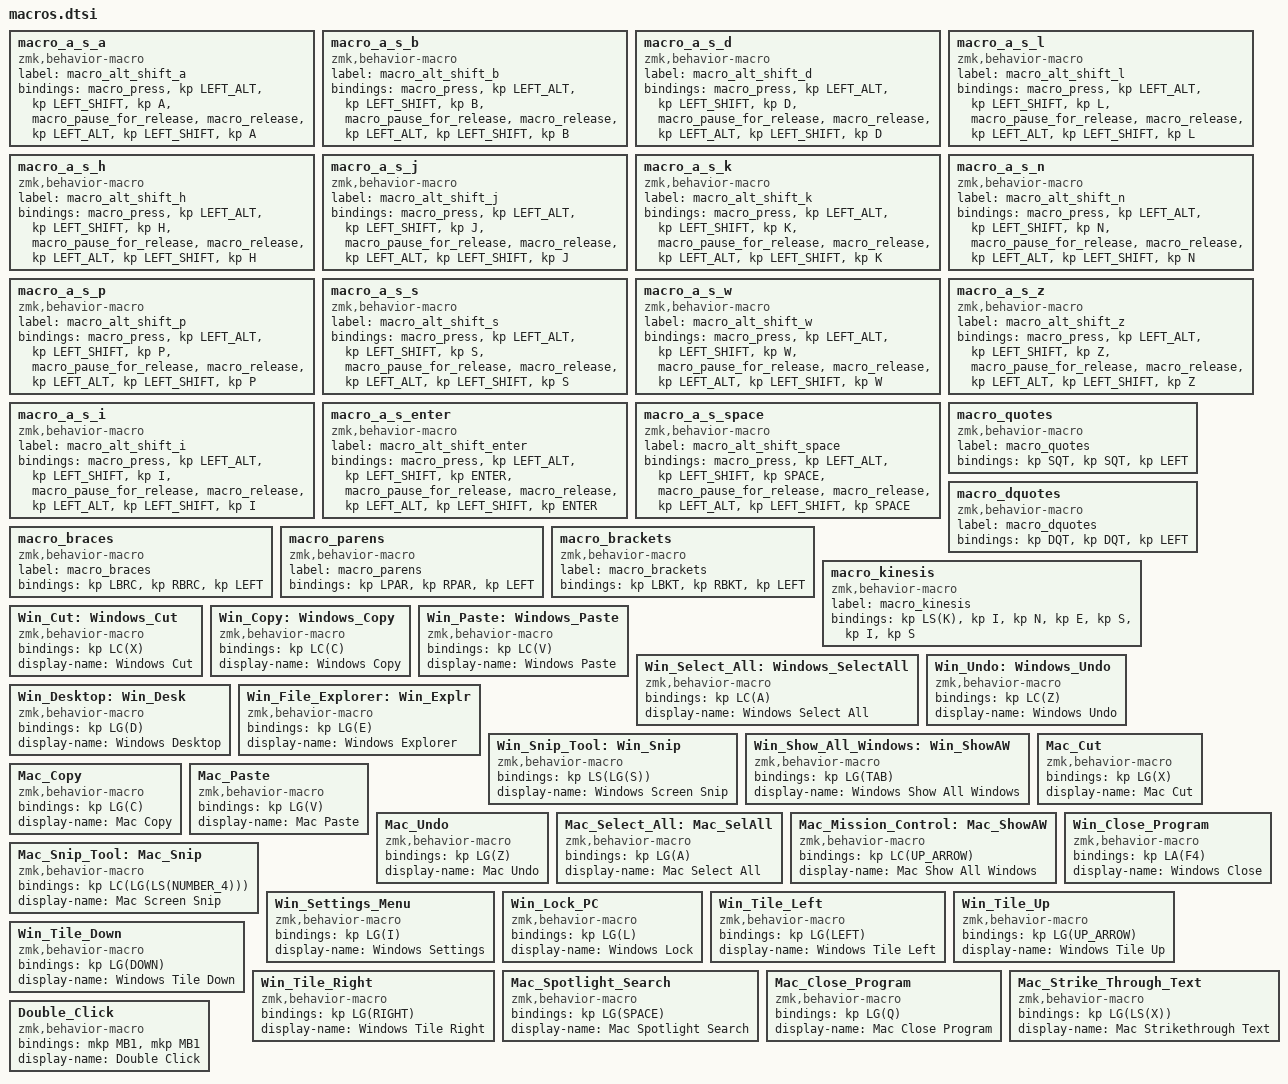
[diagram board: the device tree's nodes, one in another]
macro_a_s_a: macro_a_s_a{
compatible = "zmk,behavior-macro";
label = "macro_alt_shift_a";
#binding-cells = <0>;
bindings = <&macro_press &kp LEFT_ALT &kp LEFT_SHIFT &kp A>, <&macro_pause_for_release>, <&macro_release &kp LEFT_ALT &kp LEFT_SHIFT &kp A>;
};
macro_a_s_b: macro_a_s_b{
compatible = "zmk,behavior-macro";
label = "macro_alt_shift_b";
#binding-cells = <0>;
bindings = <&macro_press &kp LEFT_ALT &kp LEFT_SHIFT &kp B>, <&macro_pause_for_release>, <&macro_release &kp LEFT_ALT &kp LEFT_SHIFT &kp B>;
};
macro_a_s_d: macro_a_s_d{
compatible = "zmk,behavior-macro";
label = "macro_alt_shift_d";
#binding-cells = <0>;
bindings = <&macro_press &kp LEFT_ALT &kp LEFT_SHIFT &kp D>, <&macro_pause_for_release>, <&macro_release &kp LEFT_ALT &kp LEFT_SHIFT &kp D>;
};
macro_a_s_l: macro_a_s_l{
compatible = "zmk,behavior-macro";
label = "macro_alt_shift_l";
#binding-cells = <0>;
bindings = <&macro_press &kp LEFT_ALT &kp LEFT_SHIFT &kp L>, <&macro_pause_for_release>, <&macro_release &kp LEFT_ALT &kp LEFT_SHIFT &kp L>;
};
macro_a_s_h: macro_a_s_h{
compatible = "zmk,behavior-macro";
label = "macro_alt_shift_h";
#binding-cells = <0>;
bindings = <&macro_press &kp LEFT_ALT &kp LEFT_SHIFT &kp H>, <&macro_pause_for_release>, <&macro_release &kp LEFT_ALT &kp LEFT_SHIFT &kp H>;
};
macro_a_s_j: macro_a_s_j{
compatible = "zmk,behavior-macro";
label = "macro_alt_shift_j";
#binding-cells = <0>;
bindings = <&macro_press &kp LEFT_ALT &kp LEFT_SHIFT &kp J>, <&macro_pause_for_release>, <&macro_release &kp LEFT_ALT &kp LEFT_SHIFT &kp J>;
};
macro_a_s_k: macro_a_s_k{
compatible = "zmk,behavior-macro";
label = "macro_alt_shift_k";
#binding-cells = <0>;
bindings = <&macro_press &kp LEFT_ALT &kp LEFT_SHIFT &kp K>, <&macro_pause_for_release>, <&macro_release &kp LEFT_ALT &kp LEFT_SHIFT &kp K>;
};
macro_a_s_n: macro_a_s_n{
compatible = "zmk,behavior-macro";
label = "macro_alt_shift_n";
#binding-cells = <0>;
bindings = <&macro_press &kp LEFT_ALT &kp LEFT_SHIFT &kp N>, <&macro_pause_for_release>, <&macro_release &kp LEFT_ALT &kp LEFT_SHIFT &kp N>;
};
macro_a_s_p: macro_a_s_p{
compatible = "zmk,behavior-macro";
label = "macro_alt_shift_p";
#binding-cells = <0>;
bindings = <&macro_press &kp LEFT_ALT &kp LEFT_SHIFT &kp P>, <&macro_pause_for_release>, <&macro_release &kp LEFT_ALT &kp LEFT_SHIFT &kp P>;
};
macro_a_s_s: macro_a_s_s{
compatible = "zmk,behavior-macro";
label = "macro_alt_shift_s";
#binding-cells = <0>;
bindings = <&macro_press &kp LEFT_ALT &kp LEFT_SHIFT &kp S>, <&macro_pause_for_release>, <&macro_release &kp LEFT_ALT &kp LEFT_SHIFT &kp S>;
};
macro_a_s_w: macro_a_s_w{
compatible = "zmk,behavior-macro";
label = "macro_alt_shift_w";
#binding-cells = <0>;
bindings = <&macro_press &kp LEFT_ALT &kp LEFT_SHIFT &kp W>, <&macro_pause_for_release>, <&macro_release &kp LEFT_ALT &kp LEFT_SHIFT &kp W>;
};
macro_a_s_z: macro_a_s_z{
compatible = "zmk,behavior-macro";
label = "macro_alt_shift_z";
#binding-cells = <0>;
bindings = <&macro_press &kp LEFT_ALT &kp LEFT_SHIFT &kp Z>, <&macro_pause_for_release>, <&macro_release &kp LEFT_ALT &kp LEFT_SHIFT &kp Z>;
};
macro_a_s_i: macro_a_s_i{
compatible = "zmk,behavior-macro";
label = "macro_alt_shift_i";
#binding-cells = <0>;
bindings = <&macro_press &kp LEFT_ALT &kp LEFT_SHIFT &kp I>, <&macro_pause_for_release>, <&macro_release &kp LEFT_ALT &kp LEFT_SHIFT &kp I>;
};
macro_a_s_enter: macro_a_s_enter{
compatible = "zmk,behavior-macro";
label = "macro_alt_shift_enter";
#binding-cells = <0>;
bindings = <&macro_press &kp LEFT_ALT &kp LEFT_SHIFT &kp ENTER>, <&macro_pause_for_release>, <&macro_release &kp LEFT_ALT &kp LEFT_SHIFT &kp ENTER>;
};
macro_a_s_space: macro_a_s_space{
compatible = "zmk,behavior-macro";
label = "macro_alt_shift_space";
#binding-cells = <0>;
bindings = <&macro_press &kp LEFT_ALT &kp LEFT_SHIFT &kp SPACE>, <&macro_pause_for_release>, <&macro_release &kp LEFT_ALT &kp LEFT_SHIFT &kp SPACE>;
};

  macro_quotes: macro_quotes {
    compatible = "zmk,behavior-macro";
    label = "macro_quotes";
    #binding-cells = <0>;
    bindings = <&kp SQT>, <&kp SQT>, <&kp LEFT>;
  };
  macro_dquotes: macro_dquotes {
    compatible = "zmk,behavior-macro";
    label = "macro_dquotes";
    #binding-cells = <0>;
    bindings = <&kp DQT>, <&kp DQT>, <&kp LEFT>;
  };
  macro_braces: macro_braces {
    compatible = "zmk,behavior-macro";
    label = "macro_braces";
    #binding-cells = <0>;
    bindings = <&kp LBRC>, <&kp RBRC>, <&kp LEFT>;
  };
  macro_parens: macro_parens {
    compatible = "zmk,behavior-macro";
    label = "macro_parens";
    #binding-cells = <0>;
    bindings = <&kp LPAR>, <&kp RPAR>, <&kp LEFT>;
  };
  macro_brackets: macro_brackets {
    compatible = "zmk,behavior-macro";
    label = "macro_brackets";
    #binding-cells = <0>;
    bindings = <&kp LBKT>, <&kp RBKT>, <&kp LEFT>;
  };
  macro_kinesis: macro_kinesis {
    compatible = "zmk,behavior-macro";
    label = "macro_kinesis";
    #binding-cells = <0>;
    bindings = <&kp LS(K)>, <&kp I>, <&kp N>, <&kp E>, <&kp S>, <&kp I>, <&kp S>;
  };
  Win_Cut: Windows_Cut {
    compatible = "zmk,behavior-macro";
    #binding-cells = <0>;
    bindings = <&kp LC(X)>;
    display-name = "Windows Cut";
  };

  Win_Copy: Windows_Copy {
    compatible = "zmk,behavior-macro";
    #binding-cells = <0>;
    bindings = <&kp LC(C)>;
    display-name = "Windows Copy";
  };

  Win_Paste: Windows_Paste {
    compatible = "zmk,behavior-macro";
    #binding-cells = <0>;
    bindings = <&kp LC(V)>;
    display-name = "Windows Paste";
  };

  Win_Select_All: Windows_SelectAll {
      compatible = "zmk,behavior-macro";
      #binding-cells = <0>;
      bindings = <&kp LC(A)>;
      display-name = "Windows Select All";
  };

  Win_Undo: Windows_Undo {
    compatible = "zmk,behavior-macro";
    #binding-cells = <0>;
    bindings = <&kp LC(Z)>;
    display-name = "Windows Undo";
  };

  Win_Desktop: Win_Desk {
    compatible = "zmk,behavior-macro";
    #binding-cells = <0>;
    bindings = <&kp LG(D)>;
    display-name = "Windows Desktop";
  };

  Win_File_Explorer: Win_Explr {
    compatible = "zmk,behavior-macro";
    #binding-cells = <0>;
    bindings = <&kp LG(E)>;
    display-name = "Windows Explorer";
  };

  Win_Snip_Tool: Win_Snip {
    compatible = "zmk,behavior-macro";
    #binding-cells = <0>;
    bindings = <&kp LS(LG(S))>;
    display-name = "Windows Screen Snip";
  };

  Win_Show_All_Windows: Win_ShowAW {
    compatible = "zmk,behavior-macro";
    #binding-cells = <0>;
    bindings = <&kp LG(TAB)>;
    display-name = "Windows Show All Windows";
  };

  Mac_Cut: Mac_Cut {
    compatible = "zmk,behavior-macro";
    #binding-cells = <0>;
    bindings = <&kp LG(X)>;
    display-name = "Mac Cut";
  };

  Mac_Copy: Mac_Copy {
    compatible = "zmk,behavior-macro";
    #binding-cells = <0>;
    bindings = <&kp LG(C)>;
    display-name = "Mac Copy";
  };

  Mac_Paste: Mac_Paste {
    compatible = "zmk,behavior-macro";
    #binding-cells = <0>;
    bindings = <&kp LG(V)>;
    display-name = "Mac Paste";
  };

  Mac_Undo: Mac_Undo {
    compatible = "zmk,behavior-macro";
    #binding-cells = <0>;
    bindings = <&kp LG(Z)>;
    display-name = "Mac Undo";
  };

  Mac_Select_All: Mac_SelAll {
    compatible = "zmk,behavior-macro";
    #binding-cells = <0>;
    bindings = <&kp LG(A)>;
    display-name = "Mac Select All";
  };

  Mac_Mission_Control: Mac_ShowAW {
    compatible = "zmk,behavior-macro";
    #binding-cells = <0>;
    bindings = <&kp LC(UP_ARROW)>;
    display-name = "Mac Show All Windows";
  };

  Mac_Snip_Tool: Mac_Snip {
    compatible = "zmk,behavior-macro";
    #binding-cells = <0>;
    bindings = <&kp LC(LG(LS(NUMBER_4)))>;
    display-name = "Mac Screen Snip";
  };

  Win_Close_Program: Win_Close_Program {
    compatible = "zmk,behavior-macro";
    #binding-cells = <0>;
    bindings = <&kp LA(F4)>;
    display-name = "Windows Close";
  };

  Win_Settings_Menu: Win_Settings_Menu {
    compatible = "zmk,behavior-macro";
    #binding-cells = <0>;
    bindings = <&kp LG(I)>;
    display-name = "Windows Settings";
  };

  Win_Lock_PC: Win_Lock_PC {
    compatible = "zmk,behavior-macro";
    #binding-cells = <0>;
    bindings = <&kp LG(L)>;
    display-name = "Windows Lock";
  };

  Win_Tile_Left: Win_Tile_Left {
    compatible = "zmk,behavior-macro";
    #binding-cells = <0>;
    bindings = <&kp LG(LEFT)>;
    display-name = "Windows Tile Left";
  };

  Win_Tile_Up: Win_Tile_Up {
    compatible = "zmk,behavior-macro";
    #binding-cells = <0>;
    bindings = <&kp LG(UP_ARROW)>;
    display-name = "Windows Tile Up";
  };

  Win_Tile_Down: Win_Tile_Down {
    compatible = "zmk,behavior-macro";
    #binding-cells = <0>;
    bindings = <&kp LG(DOWN)>;
    display-name = "Windows Tile Down";
  };

  Win_Tile_Right: Win_Tile_Right {
    compatible = "zmk,behavior-macro";
    #binding-cells = <0>;
    bindings = <&kp LG(RIGHT)>;
    display-name = "Windows Tile Right";
  };

  Mac_Spotlight_Search: Mac_Spotlight_Search {
    compatible = "zmk,behavior-macro";
    #binding-cells = <0>;
    bindings = <&kp LG(SPACE)>;
    display-name = "Mac Spotlight Search";
  };

  Mac_Close_Program: Mac_Close_Program {
    compatible = "zmk,behavior-macro";
    #binding-cells = <0>;
    bindings = <&kp LG(Q)>;
    display-name = "Mac Close Program";
  };

  Mac_Strike_Through_Text: Mac_Strike_Through_Text {
    compatible = "zmk,behavior-macro";
    #binding-cells = <0>;
    bindings = <&kp LG(LS(X))>;
    display-name = "Mac Strikethrough Text";
  };

  Double_Click: Double_Click {
    compatible = "zmk,behavior-macro";
    #binding-cells = <0>;
    bindings = <&mkp MB1 &mkp MB1>;
    display-name = "Double Click";
  };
